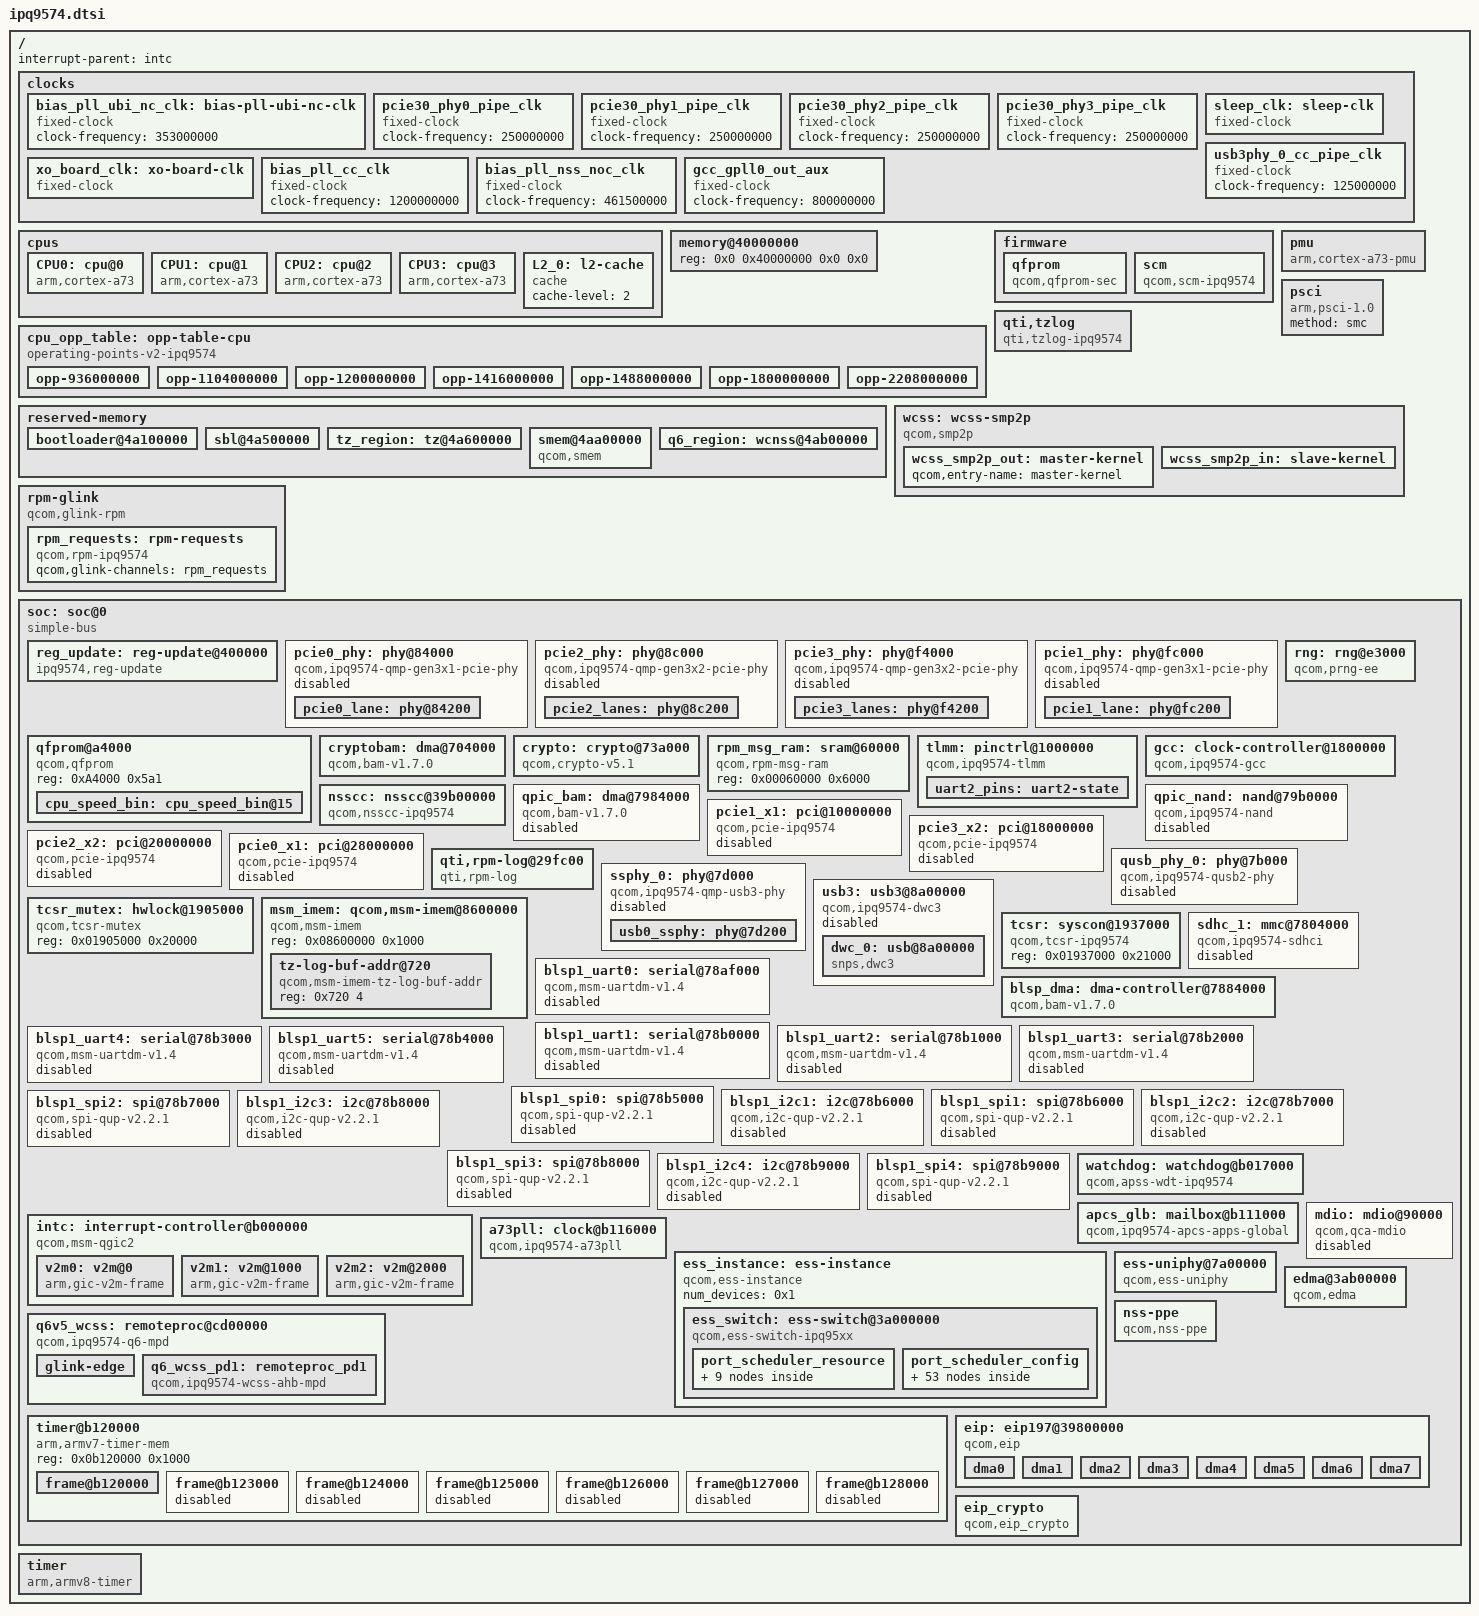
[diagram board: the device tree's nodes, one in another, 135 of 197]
// SPDX-License-Identifier: (GPL-2.0+ OR BSD-3-Clause)
/*
 * IPQ9574 SoC device tree source
 *
 * Copyright (c) 2020-2021 The Linux Foundation. All rights reserved.
 * Copyright (c) 2022-2023 Qualcomm Innovation Center, Inc. All rights reserved.
 */

#include <dt-bindings/clock/qcom,apss-ipq.h>
#include <dt-bindings/clock/qcom,ipq9574-gcc.h>
#include <dt-bindings/interrupt-controller/arm-gic.h>
#include <dt-bindings/reset/qcom,ipq9574-gcc.h>
#include <dt-bindings/clock/qcom,nsscc-ipq9574.h>
#include <dt-bindings/reset/qcom,nsscc-ipq9574.h>


/ {
	interrupt-parent = <&intc>;
	#address-cells = <2>;
	#size-cells = <2>;

	clocks {
		bias_pll_ubi_nc_clk: bias-pll-ubi-nc-clk {
			compatible = "fixed-clock";
			clock-frequency = <353000000>;
			#clock-cells = <0>;
		};

		pcie30_phy0_pipe_clk: pcie30_phy0_pipe_clk {
			compatible = "fixed-clock";
			clock-frequency = <250000000>;
			#clock-cells = <0>;
		};

		pcie30_phy1_pipe_clk: pcie30_phy1_pipe_clk {
			compatible = "fixed-clock";
			clock-frequency = <250000000>;
			#clock-cells = <0>;
		};

		pcie30_phy2_pipe_clk: pcie30_phy2_pipe_clk {
			compatible = "fixed-clock";
			clock-frequency = <250000000>;
			#clock-cells = <0>;
		};

		pcie30_phy3_pipe_clk: pcie30_phy3_pipe_clk {
			compatible = "fixed-clock";
			clock-frequency = <250000000>;
			#clock-cells = <0>;
		};

		sleep_clk: sleep-clk {
			compatible = "fixed-clock";
			#clock-cells = <0>;
		};

		usb3phy_0_cc_pipe_clk: usb3phy_0_cc_pipe_clk {
			compatible = "fixed-clock";
			clock-frequency = <125000000>;
			#clock-cells = <0>;
		};

		xo_board_clk: xo-board-clk {
			compatible = "fixed-clock";
			#clock-cells = <0>;
		};

                bias_pll_cc_clk: bias_pll_cc_clk {
                        compatible = "fixed-clock";
                        clock-frequency = <1200000000>;
                        #clock-cells = <0>;
                };

                bias_pll_nss_noc_clk: bias_pll_nss_noc_clk {
                        compatible = "fixed-clock";
                        clock-frequency = <461500000>;
                        #clock-cells = <0>;
                };

                gcc_gpll0_out_aux: gcc_gpll0_out_aux {
                        compatible = "fixed-clock";
                        clock-frequency = <800000000>;
                        #clock-cells = <0>;
                };
	};

	cpus {
		#address-cells = <1>;
		#size-cells = <0>;

		CPU0: cpu@0 {
			device_type = "cpu";
			compatible = "arm,cortex-a73";
			reg = <0x0>;
			enable-method = "psci";
			next-level-cache = <&L2_0>;
			clocks = <&apcs_glb APCS_ALIAS0_CORE_CLK>;
			clock-names = "cpu";
			operating-points-v2 = <&cpu_opp_table>;
			cpu-supply = <&ipq9574_s1>;
		};

		CPU1: cpu@1 {
			device_type = "cpu";
			compatible = "arm,cortex-a73";
			reg = <0x1>;
			enable-method = "psci";
			next-level-cache = <&L2_0>;
			clocks = <&apcs_glb APCS_ALIAS0_CORE_CLK>;
			clock-names = "cpu";
			operating-points-v2 = <&cpu_opp_table>;
			cpu-supply = <&ipq9574_s1>;
		};

		CPU2: cpu@2 {
			device_type = "cpu";
			compatible = "arm,cortex-a73";
			reg = <0x2>;
			enable-method = "psci";
			next-level-cache = <&L2_0>;
			clocks = <&apcs_glb APCS_ALIAS0_CORE_CLK>;
			clock-names = "cpu";
			operating-points-v2 = <&cpu_opp_table>;
			cpu-supply = <&ipq9574_s1>;
		};

		CPU3: cpu@3 {
			device_type = "cpu";
			compatible = "arm,cortex-a73";
			reg = <0x3>;
			enable-method = "psci";
			next-level-cache = <&L2_0>;
			clocks = <&apcs_glb APCS_ALIAS0_CORE_CLK>;
			clock-names = "cpu";
			operating-points-v2 = <&cpu_opp_table>;
			cpu-supply = <&ipq9574_s1>;
		};

		L2_0: l2-cache {
			compatible = "cache";
			cache-level = <2>;
		};
	};

	memory@40000000 {
		device_type = "memory";
		/* We expect the bootloader to fill in the size */
		reg = <0x0 0x40000000 0x0 0x0>;
	};

	cpu_opp_table: opp-table-cpu {
		compatible = "operating-points-v2-ipq9574";
		opp-shared;
		nvmem-cells = <&cpu_speed_bin>;
		nvmem-cell-names = "speed_bin";

		/* Listed all supported CPU frequencies and opp-supported-hw
		 * values to select CPU frequencies based on the limits fused.
		 * ------------------------------------------------------------
		 * Frequency     BIT3   BIT2   BIT1    BIT0    opp-supported-hw
		 *              1.2GHz 1.5GHz 1.8GHz No Limit
		 * ------------------------------------------------------------
		 * 936000000      1      1      1       1            0xF
		 * 1104000000     1      1      1       1            0xF
		 * 1200000000     1      0      0       0            0x8
		 * 1416000000     0      1      1       1            0x7
		 * 1488000000     0      1      0       0            0x4
		 * 1800000000     0      0      1       1            0x3
		 * 2208000000     0      0      0       1            0x1
		 * -----------------------------------------------------------*/

		opp-936000000 {
			opp-hz = /bits/ 64 <936000000>;
			opp-microvolt = <725000>;
			opp-supported-hw = <0xF>;
			clock-latency-ns = <200000>;
		};

		opp-1104000000 {
			opp-hz = /bits/ 64 <1104000000>;
			opp-microvolt = <787500>;
			opp-supported-hw = <0xF>;
			clock-latency-ns = <200000>;
		};

		opp-1200000000 {
			opp-hz = /bits/ 64 <1200000000>;
			opp-microvolt = <862500>;
			opp-supported-hw = <0x8>;
			clock-latency-ns = <200000>;
		};

		opp-1416000000 {
			opp-hz = /bits/ 64 <1416000000>;
			opp-microvolt = <862500>;
			opp-supported-hw = <0x7>;
			clock-latency-ns = <200000>;
		};

		opp-1488000000 {
			opp-hz = /bits/ 64 <1488000000>;
			opp-microvolt = <925000>;
			opp-supported-hw = <0x7>;
			clock-latency-ns = <200000>;
		};

		opp-1800000000 {
			opp-hz = /bits/ 64 <1800000000>;
			opp-microvolt = <987500>;
			opp-supported-hw = <0x3>;
			clock-latency-ns = <200000>;
		};

		opp-2208000000 {
			opp-hz = /bits/ 64 <2208000000>;
			opp-microvolt = <1062500>;
			opp-supported-hw = <0x1>;
			clock-latency-ns = <200000>;
		};
	};

	firmware {
		qfprom {
			compatible = "qcom,qfprom-sec";
			img-addr = <0x4a100000>;
			img-size = <0x500000>;
			scm-cmd-id = <0x1f>;
		};

		scm {
			compatible = "qcom,scm-ipq9574", "qcom,scm";
			hvc-log-cmd-id = <0xA>;
			smmu-state-cmd-id = <0x20>;
			qcom,dload-mode = <&tcsr 0x6100>;
		};
	};

	pmu {
		compatible = "arm,cortex-a73-pmu";
		interrupts = <GIC_PPI 7 (GIC_CPU_MASK_SIMPLE(4) | IRQ_TYPE_LEVEL_HIGH)>;
	};

	psci {
		compatible = "arm,psci-1.0";
		method = "smc";
	};

	qti,tzlog {
		compatible = "qti,tzlog-ipq9574";
		interrupts = <GIC_SPI 244 IRQ_TYPE_EDGE_RISING>;
		qti,tz-diag-buf-size = <0x3000>;
		qti,tz-ring-off = <7>;
		qti,tz-log-pos-info-off = <810>;
		qti,hvc-enabled;
		qti,get-smmu-state;
	};

	reserved-memory {
		#address-cells = <2>;
		#size-cells = <2>;
		ranges;

		bootloader@4a100000 {
			reg = <0x0 0x4a100000 0x0 0x00400000>;
			no-map;
		};

		sbl@4a500000 {
			reg = <0x0 0x4a500000 0x0 0x00100000>;
			no-map;
		};

		tz_region: tz@4a600000 {
			reg = <0x0 0x4a600000 0x0 0x400000>;
			no-map;
		};

		smem@4aa00000 {
			compatible = "qcom,smem";
			reg = <0x0 0x4aa00000 0x0 0x00100000>;
			hwlocks = <&tcsr_mutex 0>;
			no-map;
		};

		q6_region: wcnss@4ab00000 {
			reg = <0x0 0x4ab00000 0x0 0x02b00000>;
			no-map;
		};

	};

	wcss: wcss-smp2p {
		compatible = "qcom,smp2p";
		qcom,smem = <435>, <428>;

		interrupt-parent = <&intc>;
		interrupts = <GIC_SPI 322 IRQ_TYPE_EDGE_RISING>;

		mboxes = <&apcs_glb 9>;

		qcom,local-pid = <0>;
		qcom,remote-pid = <1>;

		wcss_smp2p_out: master-kernel {
			qcom,entry-name = "master-kernel";
			#qcom,smem-state-cells = <1>;
		};

		wcss_smp2p_in: slave-kernel {
			qcom,entry-name = "slave-kernel";
			interrupt-controller;
			#interrupt-cells = <2>;
		};
	};

	rpm-glink {
		compatible = "qcom,glink-rpm";
		interrupts = <GIC_SPI 168 IRQ_TYPE_EDGE_RISING>;
		qcom,rpm-msg-ram = <&rpm_msg_ram>;
		mboxes = <&apcs_glb 0>;

		rpm_requests: rpm-requests {
			compatible = "qcom,rpm-ipq9574";
			qcom,glink-channels = "rpm_requests";
		};
	};

	soc: soc@0 {
		compatible = "simple-bus";
		#address-cells = <1>;
		#size-cells = <1>;
		ranges = <0 0 0 0xffffffff>;

		reg_update: reg-update@400000 {
			compatible = "ipq9574,reg-update";
			reg = <0x00400000 0x6148>,
			      <0x39d00020 0x10>;
			reg-names = "memnoc",
				    "ubicore";
			clocks = <&nsscc NSS_CC_NSS_CSR_CLK>,
				 <&nsscc NSS_CC_NSSNOC_NSS_CSR_CLK>;
			clock-names = "nss-csr-clk",
				      "nss-nssnoc-csr-clk";
			assigned-clocks = <&nsscc NSS_CC_NSS_CSR_CLK>,
					  <&nsscc NSS_CC_NSSNOC_NSS_CSR_CLK>;
			assigned-clock-rates = <100000000>,
					       <100000000>;
			status = "okay";
		};

		pcie0_phy: phy@84000 {
			compatible = "qcom,ipq9574-qmp-gen3x1-pcie-phy";
			reg = <0x00084000 0x1bc>; /* Serdes PLL */
			#address-cells = <1>;
			#size-cells = <1>;
			ranges;
			clocks = <&gcc GCC_PCIE0_AUX_CLK>,
				 <&gcc GCC_PCIE0_AHB_CLK>,
				 <&gcc GCC_ANOC_PCIE0_1LANE_M_CLK>,
				 <&gcc GCC_SNOC_PCIE0_1LANE_S_CLK>;
			clock-names = "aux", "cfg_ahb", "anoc_lane", "snoc_lane";

			assigned-clocks = <&gcc GCC_PCIE0_AUX_CLK>;
			assigned-clock-rates = <20000000>;

			resets = <&gcc GCC_PCIE0_PHY_BCR>,
				 <&gcc GCC_PCIE0PHY_PHY_BCR>;
			reset-names = "phy", "common";

			status = "disabled";

			pcie0_lane: phy@84200 {
				reg = <0x00084200 0x16c>, /* Serdes Tx */
				      <0x00084400 0x200>, /* Serdes Rx */
				      <0x00084800 0x1f0>, /* PCS: Lane0, COM, PCIE */
				      <0x00084c00 0xf4>;  /* pcs_misc */
				#phy-cells = <0>;

				clocks = <&gcc GCC_PCIE0_PIPE_CLK>;
				clock-names = "pipe0";
				clock-output-names = "gcc_pcie0_pipe_clk_src";
				#clock-cells = <0>;
			};
		};

		pcie2_phy: phy@8c000 {
			compatible = "qcom,ipq9574-qmp-gen3x2-pcie-phy";
			reg = <0x0008c000 0x1bc>; /* Serdes PLL */
			#address-cells = <1>;
			#size-cells = <1>;
			ranges;

			clocks = <&gcc GCC_PCIE2_AUX_CLK>,
				 <&gcc GCC_PCIE2_AHB_CLK>,
				 <&gcc GCC_ANOC_PCIE2_2LANE_M_CLK>,
				 <&gcc GCC_SNOC_PCIE2_2LANE_S_CLK>;
			clock-names = "aux", "cfg_ahb", "anoc_lane", "snoc_lane";

			assigned-clocks = <&gcc GCC_PCIE2_AUX_CLK>;
			assigned-clock-rates = <20000000>;

			resets = <&gcc GCC_PCIE2_PHY_BCR>,
				 <&gcc GCC_PCIE2PHY_PHY_BCR>;
			reset-names = "phy", "common";

			status = "disabled";

			pcie2_lanes: phy@8c200 {
				reg = <0x0008c200 0x16c>, /* Serdes Tx0 */
				      <0x0008c400 0x200>, /* Serdes Rx0 */
				      <0x0008d000 0x1f0>, /* PCS: Lane0, COM, PCIE */
				      <0x0008c600 0x16c>, /* Serdes Tx1 */
				      <0x0008c800 0x200>, /* Serdes Rx1 */
				      <0x0008d400 0x0f8>; /* pcs_misc */

				#phy-cells = <0>;

				clocks = <&gcc GCC_PCIE2_PIPE_CLK>;
				clock-names = "pipe0";
				clock-output-names = "gcc_pcie2_pipe_clk_src";
				#clock-cells = <0>;
			};
		};

		pcie3_phy: phy@f4000 {
			compatible = "qcom,ipq9574-qmp-gen3x2-pcie-phy";
			reg = <0x000f4000 0x1bc>; /* Serdes PLL */
			#address-cells = <1>;
			#size-cells = <1>;
			ranges;

			clocks = <&gcc GCC_PCIE3_AUX_CLK>,
				 <&gcc GCC_PCIE3_AHB_CLK>,
				 <&gcc GCC_ANOC_PCIE3_2LANE_M_CLK>,
				 <&gcc GCC_SNOC_PCIE3_2LANE_S_CLK>;
			clock-names = "aux", "cfg_ahb", "anoc_lane", "snoc_lane";

			assigned-clocks = <&gcc GCC_PCIE3_AUX_CLK>;
			assigned-clock-rates = <20000000>;

			resets = <&gcc GCC_PCIE3_PHY_BCR>,
				 <&gcc GCC_PCIE3PHY_PHY_BCR>;
			reset-names = "phy", "common";

			status = "disabled";

			pcie3_lanes: phy@f4200 {
				reg = <0x000f4200 0x16c>, /* Serdes Tx0 */
				      <0x000f4400 0x200>, /* Serdes Rx0 */
				      <0x000f5000 0x1f0>, /* PCS: Lane0, COM, PCIE */
				      <0x000f4600 0x16c>, /* Serdes Tx1 */
				      <0x000f4800 0x200>, /* Serdes Rx1 */
				      <0x000f5400 0x0f8>; /* pcs_misc */

				#phy-cells = <0>;

				clocks = <&gcc GCC_PCIE3_PIPE_CLK>;
				clock-names = "pipe0";
				clock-output-names = "gcc_pcie3_pipe_clk_src";
				#clock-cells = <0>;
			};
		};

		pcie1_phy: phy@fc000 {
			compatible = "qcom,ipq9574-qmp-gen3x1-pcie-phy";
			reg = <0x000fc000 0x1bc>; /* Serdes PLL */
			#address-cells = <1>;
			#size-cells = <1>;
			ranges;

			clocks = <&gcc GCC_PCIE1_AUX_CLK>,
			 <&gcc GCC_PCIE1_AHB_CLK>,
			 <&gcc GCC_ANOC_PCIE1_1LANE_M_CLK>,
				 <&gcc GCC_SNOC_PCIE1_1LANE_S_CLK>;
			clock-names = "aux", "cfg_ahb", "anoc_lane", "snoc_lane";

			assigned-clocks = <&gcc GCC_PCIE1_AUX_CLK>;
			assigned-clock-rates = <20000000>;

			resets = <&gcc GCC_PCIE1_PHY_BCR>,
				 <&gcc GCC_PCIE1PHY_PHY_BCR>;
			reset-names = "phy", "common";

			status = "disabled";

			pcie1_lane: phy@fc200 {
				reg = <0x000fc200 0x16c>, /* Serdes Tx */
				      <0x000fc400 0x200>, /* Serdes Rx */
				      <0x000fc800 0x1f0>, /* PCS: Lane0, COM, PCIE */
				      <0x000fcc00 0xf4>;  /* pcs_misc */
				#phy-cells = <0>;

				clocks = <&gcc GCC_PCIE1_PIPE_CLK>;
				clock-names = "pipe0";
				clock-output-names = "gcc_pcie1_pipe_clk_src";
				#clock-cells = <0>;
			};
		};

		qfprom@a4000 {
			compatible = "qcom,qfprom";
			reg = <0xA4000 0x5a1>;
			#address-cells = <1>;
			#size-cells = <1>;

			cpu_speed_bin: cpu_speed_bin@15 {
				reg = <0x15 0x2>;
				bits = <7 2>;
			};
		};

		rng: rng@e3000 {
			compatible = "qcom,prng-ee";
			reg = <0x000e3000 0x1000>;
			clocks = <&gcc GCC_PRNG_AHB_CLK>;
			clock-names = "core";
		};

		cryptobam: dma@704000 {
			compatible = "qcom,bam-v1.7.0";
			reg = <0x00704000 0x20000>;
			interrupts = <GIC_SPI 207 IRQ_TYPE_LEVEL_HIGH>;
			#dma-cells = <1>;
			qcom,ee = <1>;
			qcom,controlled-remotely;
		};

		crypto: crypto@73a000 {
			compatible = "qcom,crypto-v5.1";
			reg = <0x0073a000 0x6000>;
			clocks = <&gcc GCC_CRYPTO_AHB_CLK>,
				 <&gcc GCC_CRYPTO_AXI_CLK>,
				 <&gcc GCC_CRYPTO_CLK>;
			clock-names = "iface", "bus", "core";
			dmas = <&cryptobam 2>, <&cryptobam 3>;
			dma-names = "rx", "tx";
		};

		rpm_msg_ram: sram@60000 {
			compatible = "qcom,rpm-msg-ram";
			reg = <0x00060000 0x6000>;
		};

		tlmm: pinctrl@1000000 {
			compatible = "qcom,ipq9574-tlmm";
			reg = <0x01000000 0x300000>;
			interrupts = <GIC_SPI 208 IRQ_TYPE_LEVEL_HIGH>;
			gpio-controller;
			#gpio-cells = <2>;
			gpio-ranges = <&tlmm 0 0 65>;
			interrupt-controller;
			#interrupt-cells = <2>;

			uart2_pins: uart2-state {
				pins = "gpio34", "gpio35";
				function = "blsp2_uart";
				drive-strength = <8>;
				bias-disable;
			};
		};

		gcc: clock-controller@1800000 {
			compatible = "qcom,ipq9574-gcc";
			reg = <0x01800000 0x80000>;
			clocks = <&xo_board_clk>,
				 <&sleep_clk>,
				 <&bias_pll_ubi_nc_clk>,
				 <&pcie30_phy0_pipe_clk>,
				 <&pcie30_phy1_pipe_clk>,
				 <&pcie30_phy2_pipe_clk>,
				 <&pcie30_phy3_pipe_clk>,
				 <&usb3phy_0_cc_pipe_clk>;
			#clock-cells = <1>;
			#reset-cells = <1>;
			#power-domain-cells = <1>;
		};

                nsscc: nsscc@39b00000 {
                        compatible = "qcom,nsscc-ipq9574";
                        reg = <0x39b00000 0x80000>;
                        clocks = <&bias_pll_cc_clk>,
                                <&bias_pll_nss_noc_clk>,
                                <&bias_pll_ubi_nc_clk>,
                                <&gcc_gpll0_out_aux>,
				<&xo_board_clk>;
                        clock-names = "bias_pll_cc_clk",
                                "bias_pll_nss_noc_clk",
                                "bias_pll_ubi_nc_clk",
                                "gcc_gpll0_out_aux",
                                "xo";
                        #clock-cells = <0x1>;
                        #reset-cells = <0x1>;
                };

		qpic_bam: dma@7984000 {
			compatible = "qcom,bam-v1.7.0";
			reg = <0x7984000 0x1c000>;
			interrupts = <GIC_SPI 146 IRQ_TYPE_LEVEL_HIGH>;
			clocks = <&gcc GCC_QPIC_AHB_CLK>;
			clock-names = "bam_clk";
			#dma-cells = <1>;
			qcom,ee = <0>;
			status = "disabled";
		};

		qpic_nand: nand@79b0000 {
			compatible = "qcom,ipq9574-nand";
			reg = <0x79b0000 0x10000>;
			#address-cells = <1>;
			#size-cells = <0>;
			clocks = <&gcc GCC_QPIC_CLK>,
			<&gcc GCC_QPIC_AHB_CLK>,
			<&gcc GCC_QPIC_IO_MACRO_CLK>;
			clock-names = "core", "aon", "io_macro";

			dmas = <&qpic_bam 0>,
				<&qpic_bam 1>,
				<&qpic_bam 2>,
				<&qpic_bam 3>;
			dma-names = "tx", "rx", "cmd", "sts";
			status = "disabled";
		};

		pcie1_x1: pci@10000000 {
			compatible = "qcom,pcie-ipq9574";
			reg =  <0x10000000 0xf1d>,
			       <0x10000F20 0xa8>,
			       <0x10001000 0x1000>,
			       <0x000F8000 0x4000>,
			       <0x10100000 0x1000>,
			       <0x00618108 0x4>;
			reg-names = "dbi", "elbi", "atu", "parf", "config", "aggr_noc";
			device_type = "pci";
			linux,pci-domain = <2>;
			bus-range = <0x00 0xff>;
			num-lanes = <1>;
			#address-cells = <3>;
			#size-cells = <2>;
			axi-halt-val = <0x1e>; /* increase halt window size to 1GB */

			ranges = <0x81000000 0 0x10200000 0x10200000
				  0 0x00100000   /* downstream I/O */
				  0x82000000 0 0x10300000 0x10300000
				  0 0x07d00000>; /* non-prefetchable memory */

			#interrupt-cells = <1>;
			interrupt-map-mask = <0 0 0 0x7>;
			interrupt-map = <0 0 0 1 &intc 0 35
					IRQ_TYPE_LEVEL_HIGH>, /* int_a */
					<0 0 0 2 &intc 0 49
					IRQ_TYPE_LEVEL_HIGH>, /* int_b */
					<0 0 0 3 &intc 0 84
					IRQ_TYPE_LEVEL_HIGH>, /* int_c */
					<0 0 0 4 &intc 0 85
					IRQ_TYPE_LEVEL_HIGH>; /* int_d */

			interrupts = <GIC_SPI 25 IRQ_TYPE_LEVEL_HIGH>;
			interrupt-names = "global_irq";

			/* clocks and clock-names are used to enable the clock in CBCR */
			clocks = <&gcc GCC_PCIE1_AHB_CLK>,
				 <&gcc GCC_PCIE1_AUX_CLK>,
				 <&gcc GCC_PCIE1_AXI_M_CLK>,
				 <&gcc GCC_PCIE1_AXI_S_CLK>,
				 <&gcc GCC_PCIE1_AXI_S_BRIDGE_CLK>,
				 <&gcc GCC_PCIE1_RCHNG_CLK>;
			clock-names = "ahb",
				      "aux",
				      "axi_m",
				      "axi_s",
				      "axi_bridge",
				      "rchng";

			resets = <&gcc GCC_PCIE1_PIPE_ARES>,
				 <&gcc GCC_PCIE1_CORE_STICKY_ARES>,
				 <&gcc GCC_PCIE1_AXI_S_STICKY_ARES>,
				 <&gcc GCC_PCIE1_AXI_S_ARES>,
				 <&gcc GCC_PCIE1_AXI_M_STICKY_ARES>,
				 <&gcc GCC_PCIE1_AXI_M_ARES>,
				 <&gcc GCC_PCIE1_AUX_ARES>,
				 <&gcc GCC_PCIE1_AHB_ARES>;
			reset-names = "pipe",
				      "sticky",
				      "axi_s_sticky",
				      "axi_s",
				      "axi_m_sticky",
				      "axi_m",
				      "aux",
				      "ahb";

			phys = <&pcie1_lane>;
			phy-names = "pciephy";
			msi-parent = <&v2m0>;
			status = "disabled";
		};

		pcie3_x2: pci@18000000 {
			compatible = "qcom,pcie-ipq9574";
			reg =  <0x18000000 0xf1d>,
			       <0x18000F20 0xa8>,
			       <0x18001000 0x1000>,
			       <0x000F0000 0x4000>,
			       <0x18100000 0x1000>;
			reg-names = "dbi", "elbi", "atu", "parf", "config";
			device_type = "pci";
			linux,pci-domain = <4>;
			bus-range = <0x00 0xff>;
			num-lanes = <2>;
			#address-cells = <3>;
			#size-cells = <2>;
			axi-halt-val = <0x1e>; /* increase halt window size to 1GB */

			ranges = <0x81000000 0 0x18200000 0x18200000
				  0 0x00100000   /* downstream I/O */
				  0x82000000 0 0x18300000 0x18300000
				  0 0x07d00000>; /* non-prefetchable memory */

			#interrupt-cells = <1>;
			interrupt-map-mask = <0 0 0 0x7>;
			interrupt-map = <0 0 0 1 &intc 0 189
					 IRQ_TYPE_LEVEL_HIGH>, /* int_a */
					<0 0 0 2 &intc 0 190
					 IRQ_TYPE_LEVEL_HIGH>, /* int_b */
					<0 0 0 3 &intc 0 191
					 IRQ_TYPE_LEVEL_HIGH>, /* int_c */
					<0 0 0 4 &intc 0 192
					 IRQ_TYPE_LEVEL_HIGH>; /* int_d */

			interrupts = <GIC_SPI 188 IRQ_TYPE_LEVEL_HIGH>;
			interrupt-names = "global_irq";

			/* clocks and clock-names are used to enable the clock in CBCR */
			clocks = <&gcc GCC_PCIE3_AHB_CLK>,
				 <&gcc GCC_PCIE3_AUX_CLK>,
				 <&gcc GCC_PCIE3_AXI_M_CLK>,
				 <&gcc GCC_PCIE3_AXI_S_CLK>,
				 <&gcc GCC_PCIE3_AXI_S_BRIDGE_CLK>,
				 <&gcc GCC_PCIE3_RCHNG_CLK>;
			clock-names = "ahb",
				      "aux",
				      "axi_m",
				      "axi_s",
				      "axi_bridge",
				      "rchng";

			resets = <&gcc GCC_PCIE3_PIPE_ARES>,
				 <&gcc GCC_PCIE3_CORE_STICKY_ARES>,
				 <&gcc GCC_PCIE3_AXI_S_STICKY_ARES>,
				 <&gcc GCC_PCIE3_AXI_S_ARES>,
				 <&gcc GCC_PCIE3_AXI_M_STICKY_ARES>,
				 <&gcc GCC_PCIE3_AXI_M_ARES>,
				 <&gcc GCC_PCIE3_AUX_ARES>,
				 <&gcc GCC_PCIE3_AHB_ARES>;
			reset-names = "pipe",
				      "sticky",
				      "axi_s_sticky",
				      "axi_s",
				      "axi_m_sticky",
				      "axi_m",
				      "aux",
				      "ahb";

			phys = <&pcie3_lanes>;
			phy-names = "pciephy";
			msi-parent = <&v2m0>;
			status = "disabled";
		};

		pcie2_x2: pci@20000000 {
			compatible = "qcom,pcie-ipq9574";
			reg =  <0x20000000 0xf1d>,
			       <0x20000F20 0xa8>,
			       <0x20001000 0x1000>,
			       <0x00088000 0x4000>,
			       <0x20100000 0x1000>;
			reg-names = "dbi", "elbi", "atu", "parf", "config";
			device_type = "pci";
			linux,pci-domain = <3>;
			bus-range = <0x00 0xff>;
			num-lanes =<2>;
			#address-cells = <3>;
			#size-cells = <2>;
			axi-halt-val = <0x1e>; /* increase halt window size to 1GB */

			ranges = <0x81000000 0 0x20200000 0x20200000
				  0 0x00100000   /* downstream I/O */
				  0x82000000 0 0x20300000 0x20300000
				  0 0x07d00000>; /* non-prefetchable memory */

			#interrupt-cells = <1>;
			interrupt-map-mask = <0 0 0 0x7>;
			interrupt-map = <0 0 0 1 &intc 0 164
					 IRQ_TYPE_LEVEL_HIGH>, /* int_a */
					<0 0 0 2 &intc 0 165
					 IRQ_TYPE_LEVEL_HIGH>, /* int_b */
					<0 0 0 3 &intc 0 186
					 IRQ_TYPE_LEVEL_HIGH>, /* int_c */
					<0 0 0 4 &intc 0 187
					 IRQ_TYPE_LEVEL_HIGH>; /* int_d */

			interrupts = <GIC_SPI 125 IRQ_TYPE_LEVEL_HIGH>;
			interrupt-names = "global_irq";

			/* clocks and clock-names are used to enable the clock in CBCR */
			clocks = <&gcc GCC_PCIE2_AHB_CLK>,
				 <&gcc GCC_PCIE2_AUX_CLK>,
				 <&gcc GCC_PCIE2_AXI_M_CLK>,
				 <&gcc GCC_PCIE2_AXI_S_CLK>,
				 <&gcc GCC_PCIE2_AXI_S_BRIDGE_CLK>,
				 <&gcc GCC_PCIE2_RCHNG_CLK>;
			clock-names = "ahb",
				      "aux",
				      "axi_m",
				      "axi_s",
				      "axi_bridge",
				      "rchng";

			resets = <&gcc GCC_PCIE2_PIPE_ARES>,
				 <&gcc GCC_PCIE2_CORE_STICKY_ARES>,
				 <&gcc GCC_PCIE2_AXI_S_STICKY_ARES>,
				 <&gcc GCC_PCIE2_AXI_S_ARES>,
				 <&gcc GCC_PCIE2_AXI_M_STICKY_ARES>,
				 <&gcc GCC_PCIE2_AXI_M_ARES>,
				 <&gcc GCC_PCIE2_AUX_ARES>,
				 <&gcc GCC_PCIE2_AHB_ARES>;
			reset-names = "pipe",
				      "sticky",
				      "axi_s_sticky",
				      "axi_s",
				      "axi_m_sticky",
				      "axi_m",
				      "aux",
				      "ahb";

			phys = <&pcie2_lanes>;
			phy-names = "pciephy";
			msi-parent = <&v2m0>;
			status = "disabled";
		};

		pcie0_x1: pci@28000000 {
			compatible = "qcom,pcie-ipq9574";
			reg =  <0x28000000 0xf1d>,
			       <0x28000F20 0xa8>,
			       <0x28001000 0x1000>,
			       <0x00080000 0x4000>,
			       <0x28100000 0x1000>,
			       <0x00618088 0x4>;
			reg-names = "dbi", "elbi", "atu", "parf", "config", "aggr_noc";
			device_type = "pci";
			linux,pci-domain = <1>;
			bus-range = <0x00 0xff>;
			num-lanes = <1>;
			#address-cells = <3>;
			#size-cells = <2>;
			axi-halt-val = <0x1e>; /* increase halt window size to 1GB */

			ranges = <0x81000000 0 0x28200000 0x28200000
				  0 0x00100000   /* downstream I/O */
				  0x82000000 0 0x28300000 0x28300000
				  0 0x07d00000>; /* non-prefetchable memory */

			#interrupt-cells = <1>;
			interrupt-map-mask = <0 0 0 0x7>;
			interrupt-map = <0 0 0 1 &intc 0 75
					 IRQ_TYPE_LEVEL_HIGH>, /* int_a */
					<0 0 0 2 &intc 0 78
					 IRQ_TYPE_LEVEL_HIGH>, /* int_b */
					<0 0 0 3 &intc 0 79
					 IRQ_TYPE_LEVEL_HIGH>, /* int_c */
					<0 0 0 4 &intc 0 83
					 IRQ_TYPE_LEVEL_HIGH>; /* int_d */

			interrupts = <GIC_SPI 51 IRQ_TYPE_LEVEL_HIGH>;
			interrupt-names = "global_irq";

			/* clocks and clock-names are used to enable the clock in CBCR */
			clocks = <&gcc GCC_PCIE0_AHB_CLK>,
				 <&gcc GCC_PCIE0_AUX_CLK>,
				 <&gcc GCC_PCIE0_AXI_M_CLK>,
				 <&gcc GCC_PCIE0_AXI_S_CLK>,
				 <&gcc GCC_PCIE0_AXI_S_BRIDGE_CLK>,
				 <&gcc GCC_PCIE0_RCHNG_CLK>;
			clock-names = "ahb",
				      "aux",
				      "axi_m",
				      "axi_s",
				      "axi_bridge",
				      "rchng";

			resets = <&gcc GCC_PCIE0_PIPE_ARES>,
				 <&gcc GCC_PCIE0_CORE_STICKY_ARES>,
				 <&gcc GCC_PCIE0_AXI_S_STICKY_ARES>,
				 <&gcc GCC_PCIE0_AXI_S_ARES>,
				 <&gcc GCC_PCIE0_AXI_M_STICKY_ARES>,
				 <&gcc GCC_PCIE0_AXI_M_ARES>,
				 <&gcc GCC_PCIE0_AUX_ARES>,
				 <&gcc GCC_PCIE0_AHB_ARES>;
			reset-names = "pipe",
				      "sticky",
				      "axi_s_sticky",
				      "axi_s",
				      "axi_m_sticky",
				      "axi_m",
				      "aux",
				      "ahb";

			phys = <&pcie0_lane>;
			phy-names = "pciephy";
			msi-parent = <&v2m0>;
			status = "disabled";
		};

		qti,rpm-log@29fc00 {
			compatible = "qti,rpm-log";
			reg = <0x29fc00 0x4000>;
			qti,rpm-addr-phys = <0x200000>;
			qti,offset-version = <4>;
			qti,offset-page-buffer-addr = <36>;
			qti,offset-log-len = <40>;
			qti,offset-log-len-mask = <44>;
			qti,offset-page-indices = <56>;
		};

		qusb_phy_0: phy@7b000 {
			compatible = "qcom,ipq9574-qusb2-phy";
			reg = <0x07b000 0x180>;
			#phy-cells = <0>;

			clocks = <&gcc GCC_USB0_PHY_CFG_AHB_CLK>,
				<&xo_board_clk>;
			clock-names = "cfg_ahb", "ref";

			resets = <&gcc GCC_QUSB2_0_PHY_BCR>;
			status = "disabled";
		};

		ssphy_0: phy@7d000 {
			compatible = "qcom,ipq9574-qmp-usb3-phy";
			reg = <0x7d000 0x1c4>;
			#clock-cells = <1>;
			#address-cells = <1>;
			#size-cells = <1>;
			ranges;

			clocks = <&gcc GCC_USB0_AUX_CLK>,
				 <&gcc GCC_USB0_PHY_CFG_AHB_CLK>;
			clock-names = "aux", "cfg_ahb";

			resets =  <&gcc GCC_USB0_PHY_BCR>,
				 <&gcc GCC_USB3PHY_0_PHY_BCR>;
			reset-names = "phy","common";
			status = "disabled";

			usb0_ssphy: phy@7d200 {
				reg = <0x0007d200 0x130>,	/* tx */
				      <0x0007d400 0x200>,	/* rx */
				      <0x0007d800 0x1f8>,	/* pcs  */
				      <0x0007d600 0x044>;	/* pcs misc */
				#phy-cells = <0>;
				clocks = <&gcc GCC_USB0_PIPE_CLK>;
				clock-names = "pipe0";
				clock-output-names = "usb0_pipe_clk";
			};
		};

		usb3: usb3@8a00000 {
			compatible = "qcom,ipq9574-dwc3", "qcom,dwc3";
			reg = <0x8af8800 0x400>;
			#address-cells = <1>;
			#size-cells = <1>;
			ranges;

			clocks = <&gcc GCC_SNOC_USB_CLK>,
				 <&gcc GCC_ANOC_USB_AXI_CLK>,
				 <&gcc GCC_USB0_MASTER_CLK>,
				 <&gcc GCC_USB0_SLEEP_CLK>,
				 <&gcc GCC_USB0_MOCK_UTMI_CLK>;

			clock-names = "sys_noc_axi",
				      "anoc_axi",
				      "master",
				      "sleep",
				      "mock_utmi";

			assigned-clocks = <&gcc GCC_USB0_MASTER_CLK>,
					  <&gcc GCC_USB0_MOCK_UTMI_CLK>;
			assigned-clock-rates = <200000000>,
					       <24000000>;

			resets = <&gcc GCC_USB_BCR>;
			status = "disabled";

			dwc_0: usb@8a00000 {
				compatible = "snps,dwc3";
				reg = <0x8a00000 0xcd00>;
				clocks = <&gcc GCC_USB0_MOCK_UTMI_CLK>;
				clock-names = "ref";
				interrupts = <GIC_SPI 140 IRQ_TYPE_LEVEL_HIGH>;
				phys = <&qusb_phy_0>, <&usb0_ssphy>;
				phy-names = "usb2-phy", "usb3-phy";
				tx-fifo-resize;
				snps,is-utmi-l1-suspend;
				snps,hird-threshold = /bits/ 8 <0x0>;
				snps,dis_u2_susphy_quirk;
				snps,dis_u3_susphy_quirk;
				dr_mode = "host";
			};
		};

		tcsr_mutex: hwlock@1905000 {
			compatible = "qcom,tcsr-mutex";
			reg = <0x01905000 0x20000>;
			#hwlock-cells = <1>;
		};

		msm_imem: qcom,msm-imem@8600000 {
			compatible = "qcom,msm-imem";
			reg = <0x08600000 0x1000>;
			ranges = <0x0 0x08600000 0x1000>;
			#address-cells = <1>;
			#size-cells = <1>;

			tz-log-buf-addr@720 {
				compatible = "qcom,msm-imem-tz-log-buf-addr";
				reg = <0x720 4>;
			};
		};

		tcsr: syscon@1937000 {
			compatible = "qcom,tcsr-ipq9574", "syscon";
			reg = <0x01937000 0x21000>;
		};

		sdhc_1: mmc@7804000 {
			compatible = "qcom,ipq9574-sdhci", "qcom,sdhci-msm-v5";
			reg = <0x07804000 0x1000>, <0x07805000 0x1000>;
			reg-names = "hc", "cqhci";

			interrupts = <GIC_SPI 123 IRQ_TYPE_LEVEL_HIGH>,
				     <GIC_SPI 138 IRQ_TYPE_LEVEL_HIGH>;
			interrupt-names = "hc_irq", "pwr_irq";

			clocks = <&gcc GCC_SDCC1_AHB_CLK>,
				 <&gcc GCC_SDCC1_APPS_CLK>,
				 <&xo_board_clk>;
			clock-names = "iface", "core", "xo";
			non-removable;
			status = "disabled";
		};

		blsp_dma: dma-controller@7884000 {
			compatible = "qcom,bam-v1.7.0";
			reg = <0x07884000 0x2b000>;
			interrupts = <GIC_SPI 238 IRQ_TYPE_LEVEL_HIGH>;
			clocks = <&gcc GCC_BLSP1_AHB_CLK>;
			clock-names = "bam_clk";
			#dma-cells = <1>;
			qcom,ee = <0>;
		};

		blsp1_uart0: serial@78af000 {
			compatible = "qcom,msm-uartdm-v1.4", "qcom,msm-uartdm";
			reg = <0x078af000 0x200>;
			interrupts = <GIC_SPI 107 IRQ_TYPE_LEVEL_HIGH>;
			clocks = <&gcc GCC_BLSP1_UART1_APPS_CLK>,
				 <&gcc GCC_BLSP1_AHB_CLK>;
			clock-names = "core", "iface";
			status = "disabled";
		};

		blsp1_uart1: serial@78b0000 {
			compatible = "qcom,msm-uartdm-v1.4", "qcom,msm-uartdm";
			reg = <0x078b0000 0x200>;
			interrupts = <GIC_SPI 108 IRQ_TYPE_LEVEL_HIGH>;
			clocks = <&gcc GCC_BLSP1_UART2_APPS_CLK>,
				 <&gcc GCC_BLSP1_AHB_CLK>;
			clock-names = "core", "iface";
			status = "disabled";
		};

		blsp1_uart2: serial@78b1000 {
			compatible = "qcom,msm-uartdm-v1.4", "qcom,msm-uartdm";
			reg = <0x078b1000 0x200>;
			interrupts = <GIC_SPI 306 IRQ_TYPE_LEVEL_HIGH>;
			clocks = <&gcc GCC_BLSP1_UART3_APPS_CLK>,
				 <&gcc GCC_BLSP1_AHB_CLK>;
			clock-names = "core", "iface";
			status = "disabled";
		};

		blsp1_uart3: serial@78b2000 {
			compatible = "qcom,msm-uartdm-v1.4", "qcom,msm-uartdm";
			reg = <0x078b2000 0x200>;
			interrupts = <GIC_SPI 307 IRQ_TYPE_LEVEL_HIGH>;
			clocks = <&gcc GCC_BLSP1_UART4_APPS_CLK>,
				 <&gcc GCC_BLSP1_AHB_CLK>;
			clock-names = "core", "iface";
			status = "disabled";
		};

		blsp1_uart4: serial@78b3000 {
			compatible = "qcom,msm-uartdm-v1.4", "qcom,msm-uartdm";
			reg = <0x078b3000 0x200>;
			interrupts = <GIC_SPI 308 IRQ_TYPE_LEVEL_HIGH>;
			clocks = <&gcc GCC_BLSP1_UART5_APPS_CLK>,
				 <&gcc GCC_BLSP1_AHB_CLK>;
			clock-names = "core", "iface";
			status = "disabled";
		};

		blsp1_uart5: serial@78b4000 {
			compatible = "qcom,msm-uartdm-v1.4", "qcom,msm-uartdm";
			reg = <0x078b4000 0x200>;
			interrupts = <GIC_SPI 309 IRQ_TYPE_LEVEL_HIGH>;
			clocks = <&gcc GCC_BLSP1_UART6_APPS_CLK>,
				 <&gcc GCC_BLSP1_AHB_CLK>;
			clock-names = "core", "iface";
			status = "disabled";
		};

		blsp1_spi0: spi@78b5000 {
			compatible = "qcom,spi-qup-v2.2.1";
			reg = <0x078b5000 0x600>;
			#address-cells = <1>;
			#size-cells = <0>;
			interrupts = <GIC_SPI 95 IRQ_TYPE_LEVEL_HIGH>;
			clocks = <&gcc GCC_BLSP1_QUP1_SPI_APPS_CLK>,
				 <&gcc GCC_BLSP1_AHB_CLK>;
			clock-names = "core", "iface";
			dmas = <&blsp_dma 12>, <&blsp_dma 13>;
			dma-names = "tx", "rx";
			status = "disabled";
		};

		blsp1_i2c1: i2c@78b6000 {
			compatible = "qcom,i2c-qup-v2.2.1";
			reg = <0x078b6000 0x600>;
			#address-cells = <1>;
			#size-cells = <0>;
			interrupts = <GIC_SPI 96 IRQ_TYPE_LEVEL_HIGH>;
			clocks = <&gcc GCC_BLSP1_QUP2_I2C_APPS_CLK>,
				 <&gcc GCC_BLSP1_AHB_CLK>;
			clock-names = "core", "iface";
			dmas = <&blsp_dma 14>, <&blsp_dma 15>;
			dma-names = "tx", "rx";
			status = "disabled";
		};

		blsp1_spi1: spi@78b6000 {
			compatible = "qcom,spi-qup-v2.2.1";
			reg = <0x078b6000 0x600>;
			#address-cells = <1>;
			#size-cells = <0>;
			interrupts = <GIC_SPI 96 IRQ_TYPE_LEVEL_HIGH>;
			clocks = <&gcc GCC_BLSP1_QUP2_SPI_APPS_CLK>,
				 <&gcc GCC_BLSP1_AHB_CLK>;
			clock-names = "core", "iface";
			dmas = <&blsp_dma 14>, <&blsp_dma 15>;
			dma-names = "tx", "rx";
			status = "disabled";
		};

		blsp1_i2c2: i2c@78b7000 {
			compatible = "qcom,i2c-qup-v2.2.1";
			reg = <0x078b7000 0x600>;
			#address-cells = <1>;
			#size-cells = <0>;
			interrupts = <GIC_SPI 97 IRQ_TYPE_LEVEL_HIGH>;
			clocks = <&gcc GCC_BLSP1_QUP3_I2C_APPS_CLK>,
				 <&gcc GCC_BLSP1_AHB_CLK>;
			clock-names = "core", "iface";
			dmas = <&blsp_dma 16>, <&blsp_dma 17>;
			dma-names = "tx", "rx";
			status = "disabled";
		};

		blsp1_spi2: spi@78b7000 {
			compatible = "qcom,spi-qup-v2.2.1";
			reg = <0x078b7000 0x600>;
			#address-cells = <1>;
			#size-cells = <0>;
			interrupts = <GIC_SPI 97 IRQ_TYPE_LEVEL_HIGH>;
			clocks = <&gcc GCC_BLSP1_QUP3_SPI_APPS_CLK>,
				 <&gcc GCC_BLSP1_AHB_CLK>;
			clock-names = "core", "iface";
			dmas = <&blsp_dma 16>, <&blsp_dma 17>;
			dma-names = "tx", "rx";
			status = "disabled";
		};

		blsp1_i2c3: i2c@78b8000 {
			compatible = "qcom,i2c-qup-v2.2.1";
			reg = <0x078b8000 0x600>;
			#address-cells = <1>;
			#size-cells = <0>;
			interrupts = <GIC_SPI 98 IRQ_TYPE_LEVEL_HIGH>;
			clocks = <&gcc GCC_BLSP1_QUP4_I2C_APPS_CLK>,
				 <&gcc GCC_BLSP1_AHB_CLK>;
			clock-names = "core", "iface";
			dmas = <&blsp_dma 18>, <&blsp_dma 19>;
			dma-names = "tx", "rx";
			status = "disabled";
		};

		blsp1_spi3: spi@78b8000 {
			compatible = "qcom,spi-qup-v2.2.1";
			reg = <0x078b8000 0x600>;
			#address-cells = <1>;
			#size-cells = <0>;
			interrupts = <GIC_SPI 98 IRQ_TYPE_LEVEL_HIGH>;
			spi-max-frequency = <50000000>;
			clocks = <&gcc GCC_BLSP1_QUP4_SPI_APPS_CLK>,
				 <&gcc GCC_BLSP1_AHB_CLK>;
			clock-names = "core", "iface";
			dmas = <&blsp_dma 18>, <&blsp_dma 19>;
			dma-names = "tx", "rx";
			status = "disabled";
		};

		blsp1_i2c4: i2c@78b9000 {
			compatible = "qcom,i2c-qup-v2.2.1";
			reg = <0x078b9000 0x600>;
			#address-cells = <1>;
			#size-cells = <0>;
			interrupts = <GIC_SPI 299 IRQ_TYPE_LEVEL_HIGH>;
			clocks = <&gcc GCC_BLSP1_QUP5_I2C_APPS_CLK>,
				 <&gcc GCC_BLSP1_AHB_CLK>;
			clock-names = "core", "iface";
			dmas = <&blsp_dma 20>, <&blsp_dma 21>;
			dma-names = "tx", "rx";
			status = "disabled";
		};

		blsp1_spi4: spi@78b9000 {
			compatible = "qcom,spi-qup-v2.2.1";
			reg = <0x078b9000 0x600>;
			#address-cells = <1>;
			#size-cells = <0>;
			interrupts = <GIC_SPI 299 IRQ_TYPE_LEVEL_HIGH>;
			clocks = <&gcc GCC_BLSP1_QUP5_SPI_APPS_CLK>,
				 <&gcc GCC_BLSP1_AHB_CLK>;
			clock-names = "core", "iface";
			dmas = <&blsp_dma 20>, <&blsp_dma 21>;
			dma-names = "tx", "rx";
			status = "disabled";
		};

		intc: interrupt-controller@b000000 {
			compatible = "qcom,msm-qgic2";
			reg = <0x0b000000 0x1000>,  /* GICD */
			      <0x0b002000 0x1000>,  /* GICC */
			      <0x0b001000 0x1000>,  /* GICH */
			      <0x0b004000 0x1000>;  /* GICV */
			#address-cells = <1>;
			#size-cells = <1>;
			interrupt-controller;
			#interrupt-cells = <3>;
			interrupts = <GIC_PPI 9 IRQ_TYPE_LEVEL_HIGH>;
			ranges = <0 0x0b00c000 0x3000>;

			v2m0: v2m@0 {
				compatible = "arm,gic-v2m-frame";
				reg = <0x00000000 0xffd>;
				msi-controller;
			};

			v2m1: v2m@1000 {
				compatible = "arm,gic-v2m-frame";
				reg = <0x00001000 0xffd>;
				msi-controller;
			};

			v2m2: v2m@2000 {
				compatible = "arm,gic-v2m-frame";
				reg = <0x00002000 0xffd>;
				msi-controller;
			};
		};

		watchdog: watchdog@b017000 {
			compatible = "qcom,apss-wdt-ipq9574", "qcom,kpss-wdt";
			reg = <0x0b017000 0x1000>;
			interrupts = <GIC_SPI 3 IRQ_TYPE_EDGE_RISING>;
			clocks = <&sleep_clk>;
			timeout-sec = <30>;
		};

		apcs_glb: mailbox@b111000 {
			compatible = "qcom,ipq9574-apcs-apps-global",
				     "qcom,ipq6018-apcs-apps-global";
			reg = <0x0b111000 0x1000>;
			#clock-cells = <1>;
			clocks = <&a73pll>, <&xo_board_clk>;
			clock-names = "pll", "xo";
			#mbox-cells = <1>;
		};

		a73pll: clock@b116000 {
			compatible = "qcom,ipq9574-a73pll";
			reg = <0x0b116000 0x40>;
			#clock-cells = <0>;
			clocks = <&xo_board_clk>;
			clock-names = "xo";
		};

		mdio: mdio@90000 {
			compatible = "qcom,qca-mdio", "qcom,ipq40xx-mdio";
			reg = <0x90000 0x64>;
			#address-cells = <1>;
			#size-cells = <1>;
			clocks = <&gcc GCC_MDIO_AHB_CLK>;
			clock-names = "gcc_mdio_ahb_clk";
			status = "disabled";
		};

		ess_instance: ess-instance {
			compatible = "qcom,ess-instance";
			num_devices = <0x1>;
			ess_switch: ess-switch@3a000000 {
				compatible = "qcom,ess-switch-ipq95xx";
				reg = <0x3a000000 0x1000000>;
				switch_access_mode = "local bus";
				switch_cpu_bmp = <0x1>;  /* cpu port bitmap */
				switch_inner_bmp = <0x80>; /*inner port bitmap*/
				bm_tick_mode = <0>; /* bm tick mode */
				tm_tick_mode = <0>; /* tm tick mode */
				clocks = <&gcc GCC_CMN_12GPLL_AHB_CLK>,
					<&gcc GCC_CMN_12GPLL_SYS_CLK>,
					<&gcc GCC_UNIPHY0_AHB_CLK>,
					<&gcc GCC_UNIPHY0_SYS_CLK>,
					<&gcc GCC_UNIPHY1_AHB_CLK>,
					<&gcc GCC_UNIPHY1_SYS_CLK>,
					<&gcc GCC_UNIPHY2_AHB_CLK>,
					<&gcc GCC_UNIPHY2_SYS_CLK>,
					<&gcc GCC_NSSNOC_NSSCC_CLK>,
					<&gcc GCC_NSSCC_CLK>,
					<&gcc GCC_NSSNOC_SNOC_1_CLK>,
					<&gcc GCC_NSSNOC_SNOC_CLK>,
					<&nsscc NSS_CC_PORT1_MAC_CLK>,
					<&nsscc NSS_CC_PORT2_MAC_CLK>,
					<&nsscc NSS_CC_PORT3_MAC_CLK>,
					<&nsscc NSS_CC_PORT4_MAC_CLK>,
					<&nsscc NSS_CC_PORT5_MAC_CLK>,
					<&nsscc NSS_CC_PORT6_MAC_CLK>,
					<&nsscc NSS_CC_PPE_SWITCH_CLK>,
					<&nsscc NSS_CC_PPE_SWITCH_CFG_CLK>,
					<&nsscc NSS_CC_NSSNOC_PPE_CLK>,
					<&nsscc NSS_CC_NSSNOC_PPE_CFG_CLK>,
					<&nsscc NSS_CC_PPE_EDMA_CLK>,
					<&nsscc NSS_CC_PPE_EDMA_CFG_CLK>,
					<&nsscc NSS_CC_PPE_SWITCH_IPE_CLK>,
					<&nsscc NSS_CC_PPE_SWITCH_BTQ_CLK>,
					<&nsscc NSS_CC_PORT1_RX_CLK>,
					<&nsscc NSS_CC_PORT1_TX_CLK>,
					<&nsscc NSS_CC_PORT2_RX_CLK>,
					<&nsscc NSS_CC_PORT2_TX_CLK>,
					<&nsscc NSS_CC_PORT3_RX_CLK>,
					<&nsscc NSS_CC_PORT3_TX_CLK>,
					<&nsscc NSS_CC_PORT4_RX_CLK>,
					<&nsscc NSS_CC_PORT4_TX_CLK>,
					<&nsscc NSS_CC_PORT5_RX_CLK>,
					<&nsscc NSS_CC_PORT5_TX_CLK>,
					<&nsscc NSS_CC_PORT6_RX_CLK>,
					<&nsscc NSS_CC_PORT6_TX_CLK>,
					<&nsscc NSS_CC_UNIPHY_PORT1_RX_CLK>,
					<&nsscc NSS_CC_UNIPHY_PORT1_TX_CLK>,
					<&nsscc NSS_CC_UNIPHY_PORT2_RX_CLK>,
					<&nsscc NSS_CC_UNIPHY_PORT2_TX_CLK>,
					<&nsscc NSS_CC_UNIPHY_PORT3_RX_CLK>,
					<&nsscc NSS_CC_UNIPHY_PORT3_TX_CLK>,
					<&nsscc NSS_CC_UNIPHY_PORT4_RX_CLK>,
					<&nsscc NSS_CC_UNIPHY_PORT4_TX_CLK>,
					<&nsscc NSS_CC_UNIPHY_PORT5_RX_CLK>,
					<&nsscc NSS_CC_UNIPHY_PORT5_TX_CLK>,
					<&nsscc NSS_CC_UNIPHY_PORT6_RX_CLK>,
					<&nsscc NSS_CC_UNIPHY_PORT6_TX_CLK>,
					<&nsscc NSS_CC_PORT5_RX_CLK_SRC>,
					<&nsscc NSS_CC_PORT5_TX_CLK_SRC>;
				clock-names = "cmn_ahb_clk",
					"cmn_sys_clk",
					"uniphy0_ahb_clk",
					"uniphy0_sys_clk",
					"uniphy1_ahb_clk",
					"uniphy1_sys_clk",
					"uniphy2_ahb_clk",
					"uniphy2_sys_clk",
					"gcc_nssnoc_nsscc_clk",
					"gcc_nsscc_clk",
					"gcc_nssnoc_snoc_1_clk",
					"gcc_nssnoc_snoc_clk",
					"port1_mac_clk",
					"port2_mac_clk",
					"port3_mac_clk",
					"port4_mac_clk",
					"port5_mac_clk",
					"port6_mac_clk",
					"nss_ppe_clk",
					"nss_ppe_cfg_clk",
					"nssnoc_ppe_clk",
					"nssnoc_ppe_cfg_clk",
					"nss_edma_clk",
					"nss_edma_cfg_clk",
					"nss_ppe_ipe_clk",
					"nss_ppe_btq_clk",
					"nss_port1_rx_clk", "nss_port1_tx_clk",
					"nss_port2_rx_clk", "nss_port2_tx_clk",
					"nss_port3_rx_clk", "nss_port3_tx_clk",
					"nss_port4_rx_clk", "nss_port4_tx_clk",
					"nss_port5_rx_clk", "nss_port5_tx_clk",
					"nss_port6_rx_clk", "nss_port6_tx_clk",
					"uniphy0_port1_rx_clk",
					"uniphy0_port1_tx_clk",
					"uniphy0_port2_rx_clk",
					"uniphy0_port2_tx_clk",
					"uniphy0_port3_rx_clk",
					"uniphy0_port3_tx_clk",
					"uniphy0_port4_rx_clk",
					"uniphy0_port4_tx_clk",
					"uniphy0_port5_rx_clk",
					"uniphy0_port5_tx_clk",
					"uniphy2_port6_rx_clk",
					"uniphy2_port6_tx_clk",
					"nss_port5_rx_clk_src",
					"nss_port5_tx_clk_src";
				resets = <&nsscc PPE_FULL_RESET>,
					<&nsscc UNIPHY0_SOFT_RESET>,
					<&gcc GCC_UNIPHY0_XPCS_RESET>,
					<&nsscc UNIPHY_PORT5_ARES>,
					<&gcc GCC_UNIPHY1_XPCS_RESET>,
					<&nsscc UNIPHY_PORT6_ARES>,
					<&gcc GCC_UNIPHY2_XPCS_RESET>,
					<&nsscc UNIPHY_PORT1_ARES>,
					<&nsscc UNIPHY_PORT2_ARES>,
					<&nsscc UNIPHY_PORT3_ARES>,
					<&nsscc UNIPHY_PORT4_ARES>,
					<&gcc GCC_UNIPHY0_SYS_RESET>,
					<&gcc GCC_UNIPHY1_SYS_RESET>,
					<&gcc GCC_UNIPHY2_SYS_RESET>,
					<&nsscc NSSPORT1_RESET>,
					<&nsscc NSSPORT2_RESET>,
					<&nsscc NSSPORT3_RESET>,
					<&nsscc NSSPORT4_RESET>,
					<&nsscc NSSPORT5_RESET>,
					<&nsscc NSSPORT6_RESET>,
					<&nsscc PORT1_MAC_ARES>,
					<&nsscc PORT2_MAC_ARES>,
					<&nsscc PORT3_MAC_ARES>,
					<&nsscc PORT4_MAC_ARES>,
					<&nsscc PORT5_MAC_ARES>,
					<&nsscc PORT6_MAC_ARES>;
				reset-names = "ppe_rst",
					"uniphy0_soft_rst",
					"uniphy0_xpcs_rst",
					"uniphy1_soft_rst",
					"uniphy1_xpcs_rst",
					"uniphy2_soft_rst",
					"uniphy2_xpcs_rst",
					"uniphy0_port1_dis",
					"uniphy0_port2_dis",
					"uniphy0_port3_dis",
					"uniphy0_port4_dis",
					"uniphy0_sys_rst",
					"uniphy1_sys_rst",
					"uniphy2_sys_rst",
					"nss_port1_rst",
					"nss_port2_rst",
					"nss_port3_rst",
					"nss_port4_rst",
					"nss_port5_rst",
					"nss_port6_rst",
					"nss_port1_mac_rst",
					"nss_port2_mac_rst",
					"nss_port3_mac_rst",
					"nss_port4_mac_rst",
					"nss_port5_mac_rst",
					"nss_port6_mac_rst";
				port_scheduler_resource {
					port@0 {
						port_id = <0>;
						ucast_queue = <0 63>;
						mcast_queue = <256 263>;
						l0sp = <0 0>;
						l0cdrr = <0 7>;
						l0edrr = <0 7>;
						l1cdrr = <0 0>;
						l1edrr = <0 0>;
					};
					port@1 {
						port_id = <1>;
						ucast_queue = <204 211>;
						mcast_queue = <272 275>;
						l0sp = <51 52>;
						l0cdrr = <108 115>;
						l0edrr = <108 115>;
						l1cdrr = <23 24>;
						l1edrr = <23 24>;
					};
					port@2 {
						port_id = <2>;
						ucast_queue = <212 219>;
						mcast_queue = <276 279>;
						l0sp = <53 54>;
						l0cdrr = <116 123>;
						l0edrr = <116 123>;
						l1cdrr = <25 26>;
						l1edrr = <25 26>;
					};
					port@3 {
						port_id = <3>;
						ucast_queue = <220 227>;
						mcast_queue = <280 283>;
						l0sp = <55 56>;
						l0cdrr = <124 131>;
						l0edrr = <124 131>;
						l1cdrr = <27 28>;
						l1edrr = <27 28>;
					};
					port@4 {
						port_id = <4>;
						ucast_queue = <228 235>;
						mcast_queue = <284 287>;
						l0sp = <57 58>;
						l0cdrr = <132 139>;
						l0edrr = <132 139>;
						l1cdrr = <29 30>;
						l1edrr = <29 30>;
					};
					port@5 {
						port_id = <5>;
						ucast_queue = <236 243>;
						mcast_queue = <288 291>;
						l0sp = <59 60>;
						l0cdrr = <140 147>;
						l0edrr = <140 147>;
						l1cdrr = <31 32>;
						l1edrr = <31 32>;
					};
					port@6 {
						port_id = <6>;
						ucast_queue = <244 251>;
						mcast_queue = <292 295>;
						l0sp = <61 62>;
						l0cdrr = <148 155>;
						l0edrr = <148 155>;
						l1cdrr = <33 34>;
						l1edrr = <33 34>;
					};
					port@7 {
						port_id = <7>;
						ucast_queue = <252 255>;
						mcast_queue = <296 299>;
						l0sp = <63 63>;
						l0cdrr = <156 159>;
						l0edrr = <156 159>;
						l1cdrr = <35 35>;
						l1edrr = <35 35>;
					};
					reserved {
						ucast_queue = <64 203>;
						mcast_queue = <264 271>;
						l0sp = <1 50>;
						l0cdrr = <8 107>;
						l0edrr = <8 107>;
						l1cdrr = <1 22>;
						l1edrr = <1 22>;
					};
				};
				port_scheduler_config {
					port@0 {
						port_id = <0>;
						l1scheduler {
							group@0 {
								/* L0 SP */
								sp = <0>;
								/* cpri cdrr epri edrr */
								cfg = <0 0 0 0>;
							};
						};
						l0scheduler {
							group@0 {
								/* unicast queue */
								ucast_queue = <0>;
								ucast_loop_pri = <8>;
								/* multicast queue */
								mcast_queue = <256>;
								/* sp cpri cdrr epri edrr */
								cfg = <0 0 0 0 0>;
							};
							group@1 {
								ucast_queue = <8>;
								ucast_loop_pri = <8>;
								mcast_queue = <257>;
								cfg = <0 0 0 0 0>;
							};
							group@2 {
								ucast_queue = <16>;
								ucast_loop_pri = <8>;
								mcast_queue = <258>;
								cfg = <0 0 0 0 0>;
							};
							group@3 {
								ucast_queue = <24>;
								ucast_loop_pri = <8>;
								mcast_queue = <259>;
								cfg = <0 0 0 0 0>;
							};
							group@4 {
								ucast_queue = <32>;
								ucast_loop_pri = <8>;
								mcast_queue = <260>;
								cfg = <0 0 0 0 0>;
							};
							group@5 {
								ucast_queue = <40>;
								ucast_loop_pri = <8>;
								mcast_queue = <261>;
								cfg = <0 0 0 0 0>;
							};
							group@6 {
								ucast_queue = <48>;
								ucast_loop_pri = <8>;
								mcast_queue = <262>;
								cfg = <0 0 0 0 0>;
							};
							group@7 {
								ucast_queue = <56>;
								ucast_loop_pri = <8>;
								mcast_queue = <263>;
								cfg = <0 0 0 0 0>;
							};
						};
					};
					port@1 {
						port_id = <1>;
						l1scheduler {
							group@0 {
								sp = <51>;
								cfg = <0 23 0 23>;
							};
							group@1 {
								sp = <52>;
								cfg = <1 24 1 24>;
							};
						};
						l0scheduler {
							group@0 {
								ucast_queue = <204>;
								ucast_loop_pri = <8>;
								/* max priority per SP */
								ucast_max_pri = <4>;
								mcast_queue = <272>;
								mcast_loop_pri = <4>;
								cfg = <51 0 108 0 108>;
							};
						};
					};
					port@2 {
						port_id = <2>;
						l1scheduler {
							group@0 {
								sp = <53>;
								cfg = <0 25 0 25>;
							};
							group@1 {
								sp = <54>;
								cfg = <1 26 1 26>;
							};
						};
						l0scheduler {
							group@0 {
								ucast_queue = <212>;
								ucast_loop_pri = <8>;
								ucast_max_pri = <4>;
								mcast_queue = <276>;
								mcast_loop_pri = <4>;
								cfg = <53 0 116 0 116>;
							};
						};
					};
					port@3 {
						port_id = <3>;
						l1scheduler {
							group@0 {
								sp = <55>;
								cfg = <0 27 0 27>;
							};
							group@1 {
								sp = <56>;
								cfg = <1 28 1 28>;
							};
						};
						l0scheduler {
							group@0 {
								ucast_queue = <220>;
								ucast_loop_pri = <8>;
								ucast_max_pri = <4>;
								mcast_queue = <280>;
								mcast_loop_pri = <4>;
								cfg = <55 0 124 0 124>;
							};
						};
					};
					port@4 {
						port_id = <4>;
						l1scheduler {
							group@0 {
								sp = <57>;
								cfg = <0 29 0 29>;
							};
							group@1 {
								sp = <58>;
								cfg = <1 30 1 30>;
							};
						};
						l0scheduler {
							group@0 {
								ucast_queue = <228>;
								ucast_loop_pri = <8>;
								ucast_max_pri = <4>;
								mcast_queue = <284>;
								mcast_loop_pri = <4>;
								cfg = <57 0 132 0 132>;
							};
						};
					};
					port@5 {
						port_id = <5>;
						l1scheduler {
							group@0 {
								sp = <59>;
								cfg = <0 31 0 31>;
							};
							group@1 {
								sp = <60>;
								cfg = <1 32 1 32>;
							};
						};
						l0scheduler {
							group@0 {
								ucast_queue = <236>;
								ucast_loop_pri = <8>;
								ucast_max_pri = <4>;
								mcast_queue = <288>;
								mcast_loop_pri = <4>;
								cfg = <59 0 140 0 140>;
							};
						};
					};
					port@6 {
						port_id = <6>;
						l1scheduler {
							group@0 {
								sp = <61>;
								cfg = <0 33 0 33>;
							};
							group@1 {
								sp = <62>;
								cfg = <1 34 1 34>;
							};
						};
						l0scheduler {
							group@0 {
								ucast_queue = <244>;
								ucast_loop_pri = <8>;
								ucast_max_pri = <4>;
								mcast_queue = <292>;
								mcast_loop_pri = <4>;
								cfg = <61 0 148 0 148>;
							};
						};
					};
					port@7 {
						port_id = <7>;
						l1scheduler {
							group@0 {
								sp = <63>;
								cfg = <0 35 0 35>;
							};
						};
						l0scheduler {
							group@0 {
								ucast_queue = <252>;
								ucast_loop_pri = <4>;
								ucast_max_pri = <4>;
								mcast_queue = <296>;
								mcast_loop_pri = <4>;
								cfg = <63 0 156 0 156>;
							};
						};
					};
				};
			};
		};

		ess-uniphy@7a00000 {
			compatible = "qcom,ess-uniphy";
			reg = <0x7a00000 0x30000>;
			uniphy_access_mode = "local bus";
		};

		q6v5_wcss: remoteproc@cd00000 {
			compatible = "qcom,ipq9574-q6-mpd";
			#address-cells = <1>;
			#size-cells = <1>;
			ranges;
			reg = <0x0cd00000 0x4040>;
			interrupts-extended = <&intc GIC_SPI 325 IRQ_TYPE_EDGE_RISING>,
					      <&wcss_smp2p_in 0 0>,
					      <&wcss_smp2p_in 1 0>,
					      <&wcss_smp2p_in 2 0>,
					      <&wcss_smp2p_in 3 0>;
			interrupt-names = "wdog",
					  "fatal",
					  "ready",
					  "handover",
					  "stop-ack";

			clocks = <&gcc GCC_ANOC_WCSS_AXI_M_CLK>,
				 <&gcc GCC_WCSS_AHB_S_CLK>,
				 <&gcc GCC_WCSS_ECAHB_CLK>,
				 <&gcc GCC_WCSS_ACMT_CLK>,
				 <&gcc GCC_WCSS_AXI_M_CLK>,
				 <&gcc GCC_Q6_AXIM_CLK>,
				 <&gcc GCC_Q6_AXIM2_CLK>,
				 <&gcc GCC_Q6_AHB_CLK>,
				 <&gcc GCC_Q6_AHB_S_CLK>,
				 <&gcc GCC_Q6SS_BOOT_CLK>,
				 <&gcc GCC_WCSS_DBG_IFC_APB_BDG_CLK>,
				 <&gcc GCC_WCSS_DBG_IFC_ATB_BDG_CLK>,
				 <&gcc GCC_WCSS_DBG_IFC_DAPBUS_BDG_CLK>,
				 <&gcc GCC_WCSS_DBG_IFC_NTS_BDG_CLK>,
				 <&gcc GCC_WCSS_DBG_IFC_APB_CLK>,
				 <&gcc GCC_WCSS_DBG_IFC_ATB_CLK>,
				 <&gcc GCC_WCSS_DBG_IFC_DAPBUS_CLK>,
				 <&gcc GCC_WCSS_DBG_IFC_NTS_CLK>,
				 <&gcc GCC_Q6_TSCTR_1TO2_CLK>,
				 <&gcc GCC_Q6SS_ATBM_CLK>,
				 <&gcc GCC_Q6SS_PCLKDBG_CLK>,
				 <&gcc GCC_Q6SS_TRIG_CLK>,
				 <&gcc GCC_MEM_NOC_Q6_AXI_CLK>,
				 <&gcc GCC_WCSS_Q6_TBU_CLK>,
				 <&gcc GCC_SYS_NOC_WCSS_AHB_CLK>;

			clock-names = "anoc_wcss_axi_m",
				      "wcss_ahb_s",
				      "wcss_ecahb",
				      "wcss_acmt",
				      "wcss_axi_m",
				      "q6_axim",
				      "q6_axim2",
				      "q6_ahb",
				      "q6_ahb_s",
				      "q6ss_boot",
				      "dbg-apb-bdg",
				      "dbg-atb-bdg",
				      "dbg-dapbus-bdg",
				      "dbg-nts-bdg",
				      "dbg-apb",
				      "dbg-atb",
				      "dbg-dapbus",
				      "dbg-nts",
				      "q6_tsctr_1to2_clk",
				      "q6ss_atbm_clk",
				      "q6ss_pclkdbg_clk",
				      "q6ss_trig_clk",
				      "mem_noc_q6_axi",
				      "wcss_q6_tbu",
				      "sys_noc_wcss_ahb";

			assigned-clocks = <&gcc GCC_ANOC_WCSS_AXI_M_CLK>,
				 <&gcc GCC_WCSS_AHB_S_CLK>,
				 <&gcc GCC_WCSS_ECAHB_CLK>,
				 <&gcc GCC_WCSS_ACMT_CLK>,
				 <&gcc GCC_WCSS_AXI_M_CLK>,
				 <&gcc GCC_Q6_AXIM_CLK>,
				 <&gcc GCC_Q6_AXIM2_CLK>,
				 <&gcc GCC_Q6_AHB_CLK>,
				 <&gcc GCC_Q6_AHB_S_CLK>,
				 <&gcc GCC_Q6SS_BOOT_CLK>,
				 <&gcc GCC_MEM_NOC_Q6_AXI_CLK>,
				 <&gcc GCC_WCSS_Q6_TBU_CLK>,
				 <&gcc GCC_SYS_NOC_WCSS_AHB_CLK>;

			assigned-clock-rates = <266666667>,
						<133333333>,
						<133333333>,
						<133333333>,
						<266666667>,
						<533000000>,
						<342857143>,
						<133333333>,
						<133333333>,
						<342857143>,
						<533000000>,
						<533000000>,
						<133333333>;

			qcom,smem-states = <&wcss_smp2p_out 0>,
					   <&wcss_smp2p_out 1>;
			qcom,smem-state-names = "shutdown",
						"stop";

			memory-region = <&q6_region>;

			glink-edge {
				interrupts = <GIC_SPI 321 IRQ_TYPE_EDGE_RISING>;
				label = "rtr";
				qcom,remote-pid = <1>;
				mboxes = <&apcs_glb 8>;
			};

			q6_wcss_pd1: remoteproc_pd1 {
				compatible = "qcom,ipq9574-wcss-ahb-mpd";
			};
		};

		timer@b120000 {
			compatible = "arm,armv7-timer-mem";
			reg = <0x0b120000 0x1000>;
			#address-cells = <1>;
			#size-cells = <1>;
			ranges;

			frame@b120000 {
				reg = <0x0b121000 0x1000>,
				      <0x0b122000 0x1000>;
				frame-number = <0>;
				interrupts = <GIC_SPI 8 IRQ_TYPE_LEVEL_HIGH>,
					     <GIC_SPI 7 IRQ_TYPE_LEVEL_HIGH>;
			};

			frame@b123000 {
				reg = <0x0b123000 0x1000>;
				frame-number = <1>;
				interrupts = <GIC_SPI 9 IRQ_TYPE_LEVEL_HIGH>;
				status = "disabled";
			};

			frame@b124000 {
				reg = <0x0b124000 0x1000>;
				frame-number = <2>;
				interrupts = <GIC_SPI 10 IRQ_TYPE_LEVEL_HIGH>;
				status = "disabled";
			};

			frame@b125000 {
				reg = <0x0b125000 0x1000>;
				frame-number = <3>;
				interrupts = <GIC_SPI 11 IRQ_TYPE_LEVEL_HIGH>;
				status = "disabled";
			};

			frame@b126000 {
				reg = <0x0b126000 0x1000>;
				frame-number = <4>;
				interrupts = <GIC_SPI 12 IRQ_TYPE_LEVEL_HIGH>;
				status = "disabled";
			};

			frame@b127000 {
				reg = <0x0b127000 0x1000>;
				frame-number = <5>;
				interrupts = <GIC_SPI 13 IRQ_TYPE_LEVEL_HIGH>;
				status = "disabled";
			};

			frame@b128000 {
				reg = <0x0b128000 0x1000>;
				frame-number = <6>;
				interrupts = <GIC_SPI 14 IRQ_TYPE_LEVEL_HIGH>;
				status = "disabled";
			};
		};

		edma@3ab00000 {
			compatible = "qcom,edma";
			reg = <0x3ab00000 0xef800>;
			reg-names = "edma-reg-base";
			resets = <&nsscc EDMA_HW_RESET>;
			reset-names = "edma_rst";
			clocks = <&nsscc NSS_CC_NSS_CSR_CLK>,
				 <&nsscc NSS_CC_NSSNOC_NSS_CSR_CLK>,
				 <&nsscc NSS_CC_IMEM_QSB_CLK>,
				 <&nsscc NSS_CC_NSSNOC_IMEM_QSB_CLK>,
				 <&nsscc NSS_CC_IMEM_AHB_CLK>,
				 <&nsscc NSS_CC_NSSNOC_IMEM_AHB_CLK>,
				 <&gcc GCC_MEM_NOC_NSSNOC_CLK>,
				 <&gcc GCC_NSS_TBU_CLK>,
				 <&gcc GCC_NSS_TS_CLK>,
				 <&gcc GCC_NSSCC_CLK>,
				 <&gcc GCC_NSSCFG_CLK>,
				 <&gcc GCC_NSSNOC_ATB_CLK>,
				 <&gcc GCC_NSSNOC_MEM_NOC_1_CLK>,
				 <&gcc GCC_NSSNOC_MEMNOC_CLK>,
				 <&gcc GCC_NSSNOC_NSSCC_CLK>,
				 <&gcc GCC_NSSNOC_PCNOC_1_CLK>,
				 <&gcc GCC_NSSNOC_QOSGEN_REF_CLK>,
				 <&gcc GCC_NSSNOC_SNOC_1_CLK>,
				 <&gcc GCC_NSSNOC_SNOC_CLK>,
				 <&gcc GCC_NSSNOC_TIMEOUT_REF_CLK>,
				 <&gcc GCC_NSSNOC_XO_DCD_CLK>;
			clock-names = "nss-csr-clk", "nss-nssnoc-csr-clk",
				      "nss-imem-qsb-clk", "nss-nssnoc-imem-qsb-clk",
				      "nss-imem-ahb-clk", "nss-nssnoc-imem-ahb-clk",
				      "nss-mem-noc-nssnoc-clk", "nss-tbu-clk", "nss-ts-clk",
				      "nss-nsscc-clk", "nss-nsscfg-clk", "nss-nsscnoc-atb-clk",
				      "nss-nssnoc-mem-noc-1-clk", "nss-nssnoc-memnoc-clk", "nss-nssnoc-nsscc-clk",
				      "nss-nssnoc-pcnoc-1-clk", "nss-nssnoc-qosgen-ref-clk", "nss-nssnoc-snoc-1-clk",
				      "nss-nssnoc-snoc-clk", "nss-nssnoc-timeout-ref-clk", "nss-nssnoc-xo-dcd-clk";
		};

		nss-ppe {
			compatible = "qcom,nss-ppe";
		};

		eip: eip197@39800000 {
			compatible = "qcom,eip";
			reg-names = "eip_pbase";
			reg = <0x39800000 0x7ffff>;
			reg_offset = <0x80000>;
			ranges;
			clocks = <&nsscc NSS_CC_CRYPTO_CLK>,
			<&nsscc NSS_CC_NSSNOC_CRYPTO_CLK>,
			<&nsscc NSS_CC_CRYPTO_PPE_CLK>;
			clock-names = "crypto_clk", "crypto_nocclk",
			"crypto_ppeclk";
			clock-frequency = /bits/ 64 <600000000 600000000 300000000>;
			status = "ok";
			interrupts = <GIC_SPI 385 IRQ_TYPE_LEVEL_HIGH>,
				   <GIC_SPI 386 IRQ_TYPE_LEVEL_HIGH>,
				   <GIC_SPI 387 IRQ_TYPE_LEVEL_HIGH>,
				   <GIC_SPI 388 IRQ_TYPE_LEVEL_HIGH>;

			dma0 {
				tx_cpu = /bits/ 8 <0>;
				rx_cpu = /bits/ 8 <3>;
				ring-name = "lookaside";
				ring-id = /bits/ 8 <0>;
			};

			dma1 {
				tx_cpu = /bits/ 8 <1>;
				rx_cpu = /bits/ 8 <2>;
				ring-name = "lookaside";
				ring-id = /bits/ 8 <1>;
			};

			dma2 {
				tx_cpu = /bits/ 8 <2>;
				rx_cpu = /bits/ 8 <1>;
				ring-name = "lookaside";
				ring-id = /bits/ 8 <2>;
			};

			dma3 {
				tx_cpu = /bits/ 8 <3>;
				rx_cpu = /bits/ 8 <0>;
				ring-name = "lookaside";
				ring-id = /bits/ 8 <3>;
			};

			dma4 {
				tx_cpu = /bits/ 8 <0>;
				rx_cpu = /bits/ 8 <0>;
				ring-name = "hybrid";
				ring-id = /bits/ 8 <4>;
			};

			dma5 {
				tx_cpu = /bits/ 8 <1>;
				rx_cpu = /bits/ 8 <1>;
				ring-name = "hybrid";
				ring-id = /bits/ 8 <5>;
			};

			dma6 {
				tx_cpu = /bits/ 8 <2>;
				rx_cpu = /bits/ 8 <2>;
				ring-name = "hybrid";
				ring-id = /bits/ 8 <6>;
			};

			dma7 {
				tx_cpu = /bits/ 8 <3>;
				rx_cpu = /bits/ 8 <3>;
				ring-name = "hybrid";
				ring-id = /bits/ 8 <7>;
			};
		};

		eip_crypto: eip_crypto {
			compatible = "qcom,eip_crypto";
			status = "ok";
		};

	};

	timer {
		compatible = "arm,armv8-timer";
		interrupts = <GIC_PPI 2 (GIC_CPU_MASK_SIMPLE(4) | IRQ_TYPE_LEVEL_LOW)>,
			     <GIC_PPI 3 (GIC_CPU_MASK_SIMPLE(4) | IRQ_TYPE_LEVEL_LOW)>,
			     <GIC_PPI 4 (GIC_CPU_MASK_SIMPLE(4) | IRQ_TYPE_LEVEL_LOW)>,
			     <GIC_PPI 1 (GIC_CPU_MASK_SIMPLE(4) | IRQ_TYPE_LEVEL_LOW)>;
	};
};

